# SKEAZN642 register map
Vendor: Freescale Semiconductor, Inc.; Series: Kinetis_EA; File version: 1.6
CPU: CM0PLUS r0p0, little endian, no MPU, no FPU, VTOR, 2 interrupt priority bits
Registers are 32-bit, read-write, reset 0x0 unless marked. A register's access mark holds for its fields unless they carry their own. Offsets are from the block's base; [hi:lo] are bit positions.

## WDOG — Watchdog timer
Base 0x40052000; register names take the prefix WDOG_
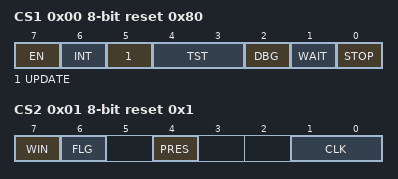
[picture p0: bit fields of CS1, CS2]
0x00 CS1 8-bit reset 0x80 — Watchdog Control and Status Register 1
  [7] EN — Watchdog Enable
    0=Watchdog disabled; 1=Watchdog enabled
  [6] INT — Watchdog Interrupt
    0=Watchdog interrupts are disabled. Watchdog resets are not delayed.; 1=Watchdog interrupts are enabled. Watchdog resets are delayed by 128 bus clocks.
  [5] UPDATE — Allow updates
    0=Updates not allowed. After the initial configuration, the watchdog cannot be later modified without forcing a reset.; 1=Updates allowed. Software can modify the watchdog configuration registers within 128 bus clocks after performing the unlock write sequence.
  [4:3] TST — Watchdog Test
    0=Watchdog test mode disabled; 1=Watchdog user mode enabled. (Watchdog test mode disabled.) After testing the watchdog, software should use this setting to indicate that the watchdog is functioning normally in user mode.; 2=Watchdog test mode enabled, only the low byte is used. WDOG_CNTL is compared with WDOG_TOVALL.; 3=Watchdog test mode enabled, only the high byte is used. WDOG_CNTH is compared with WDOG_TOVALH.
  [2] DBG — Debug Enable
    0=Watchdog disabled in chip debug mode; 1=Watchdog enabled in chip debug mode
  [1] WAIT — Wait Enable
    0=Watchdog disabled in chip wait mode; 1=Watchdog enabled in chip wait mode
  [0] STOP — Stop Enable
    0=Watchdog disabled in chip stop mode; 1=Watchdog enabled in chip stop mode
0x01 CS2 8-bit reset 0x1 — Watchdog Control and Status Register 2
  [7] WIN — Watchdog Window
    0=Window mode disabled; 1=Window mode enabled
  [6] FLG — Watchdog Interrupt Flag
    0=No interrupt occurred; 1=An interrupt occurred
  [4] PRES — Watchdog Prescalar
    0=256 prescalar disabled; 1=256 prescalar enabled
  [1:0] CLK — Watchdog Clock
    0=Bus clock; 1=1 kHz internal low-power oscillator (LPOCLK); 2=32 kHz internal oscillator (ICSIRCLK); 3=External clock source
0x02 CNT 16-bit (WDOG view) — Watchdog Counter Register.
  [15:0] CNT — Watchdog Counter Value
0x02 CNTH 8-bit ro (WDOG view) — Watchdog Counter Register: High
  [7:0] CNTHIGH — High byte of the Watchdog Counter
0x03 CNTL 8-bit ro — Watchdog Counter Register: Low
  [7:0] CNTLOW — Low byte of the Watchdog Counter
0x04 TOVAL 16-bit (WDOG view) — Watchdog Timeout Value Register.
  [15:0] TOVAL — Watchdog Timeout Value
0x04 TOVALH 8-bit (WDOG view) — Watchdog Timeout Value Register: High
  [7:0] TOVALHIGH — High byte of the timeout value
0x05 TOVALL 8-bit reset 0x4 — Watchdog Timeout Value Register: Low
  [7:0] TOVALLOW — Low byte of the timeout value
0x06 WIN 16-bit (WDOG view) — Watchdog Window Register.
  [15:0] WIN — Watchdog Window Value
0x06 WINH 8-bit (WDOG view) — Watchdog Window Register: High
  [7:0] WINHIGH — High byte of Watchdog Window
0x07 WINL 8-bit — Watchdog Window Register: Low
  [7:0] WINLOW — Low byte of Watchdog Window

## ICS — Clock management
Base 0x40064000; register names take the prefix ICS_
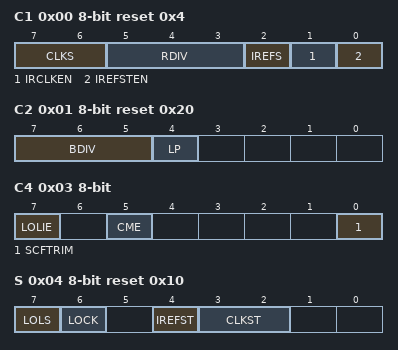
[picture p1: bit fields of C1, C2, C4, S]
0x00 C1 8-bit reset 0x4 — ICS Control Register 1
  [7:6] CLKS — Clock Source Select
    0=Output of FLL is selected; 1=Internal reference clock is selected; 2=External reference clock is selected; 3=Reserved, defaults to 00
  [5:3] RDIV — Reference Divider
  [2] IREFS — Internal Reference Select
    0=External reference clock is selected; 1=Internal reference clock is selected
  [1] IRCLKEN — Internal Reference Clock Enable
    0=ICSIRCLK is inactive; 1=ICSIRCLK is active
  [0] IREFSTEN — Internal Reference Stop Enable
    0=Internal reference clock is disabled in Stop mode; 1=Internal reference clock stays enabled in Stop mode if IRCLKEN is set, or if ICS is in FEI, FBI, or FBILP mode before entering Stop
0x01 C2 8-bit reset 0x20 — ICS Control Register 2
  [7:5] BDIV — Bus Frequency Divider
    0=Encoding 0-Divides the selected clock by 1; 1=Encoding 1-Divides the selected clock by 2 (reset default); 2=Encoding 2-Divides the selected clock by 4; 3=Encoding 3-Divides the selected clock by 8; 4=Encoding 4-Divides the selected clock by 16; 5=Encoding 5-Divides the selected clock by 32; 6=Encoding 6-Divides the selected clock by 64; 7=Encoding 7-Divides the selected clock by 128
  [4] LP — Low Power Select
    0=FLL is not disabled in bypass mode; 1=FLL is disabled in bypass modes unless debug is active
0x02 C3 8-bit reset not defined — ICS Control Register 3
  [7:0] SCTRIM — Slow Internal Reference Clock Trim Setting
0x03 C4 8-bit (reset mask 0xFE) — ICS Control Register 4
  [7] LOLIE — Loss of Lock Interrupt
    0=No request on loss of lock; 1=Generates an interrupt request on loss of lock
  [5] CME — Clock Monitor Enable
    0=Clock monitor is disabled; 1=Generates a reset request on loss of external clock
  [0] SCFTRIM — Slow Internal Reference Clock Fine Trim
0x04 S 8-bit ro reset 0x10 — ICS Status Register
  [7] LOLS — Loss of Lock Status
    0=FLL has not lost lock since LOLS was last cleared; 1=FLL has lost lock since LOLS was last cleared
  [6] LOCK — Lock Status
    0=FLL is currently unlocked; 1=FLL is currently locked
  [4] IREFST — Internal Reference Status
    0=Source of reference clock is external clock; 1=Source of reference clock is internal clock
  [3:2] CLKST — Clock Mode Status
    0=Output of FLL is selected; 1=FLL Bypassed, internal reference clock is selected; 2=FLL Bypassed, external reference clock is selected
